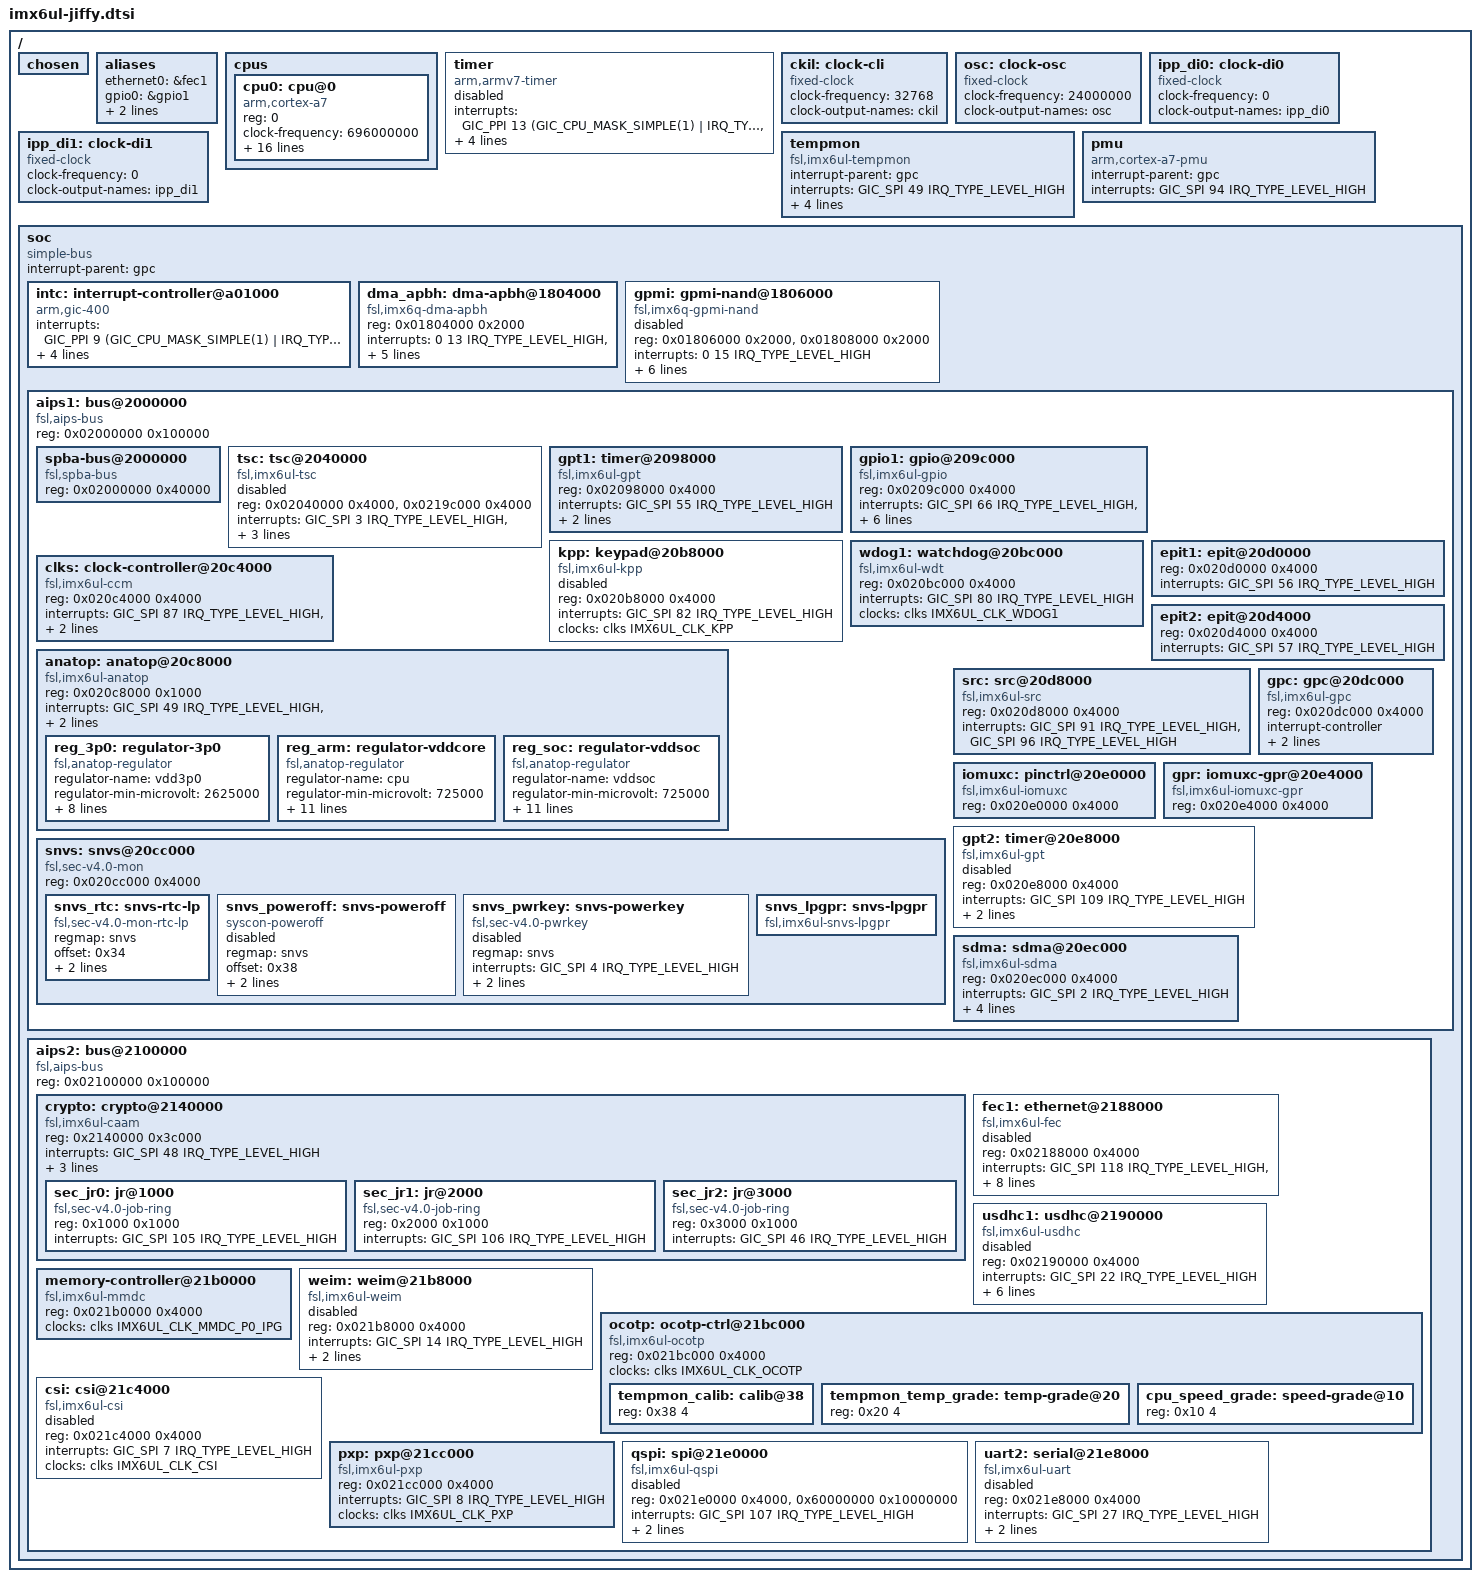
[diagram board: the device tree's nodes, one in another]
// SPDX-License-Identifier: GPL-2.0
//
// Copyright 2015 Freescale Semiconductor, Inc.

#include <dt-bindings/clock/imx6ul-clock.h>
#include <dt-bindings/gpio/gpio.h>
#include <dt-bindings/input/input.h>
#include <dt-bindings/interrupt-controller/arm-gic.h>
#include "imx6ul-pinfunc.h"

/ {
	#address-cells = <1>;
	#size-cells = <1>;
	/*
	 * The decompressor and also some bootloaders rely on a
	 * pre-existing /chosen node to be available to insert the
	 * command line and merge other ATAGS info.
	 */
	chosen {};

	aliases {
		ethernet0 = &fec1;
		gpio0 = &gpio1;
		mmc0 = &usdhc1;
		serial1 = &uart2;
	};

	cpus {
		#address-cells = <1>;
		#size-cells = <0>;

		cpu0: cpu@0 {
			compatible = "arm,cortex-a7";
			device_type = "cpu";
			reg = <0>;
			clock-frequency = <696000000>;
			clock-latency = <61036>; /* two CLK32 periods */
			#cooling-cells = <2>;
			operating-points = <
				/* kHz	uV */
				696000	1275000
				528000	1175000
				396000	1025000
				198000	950000
			>;
			fsl,soc-operating-points = <
				/* KHz	uV */
				696000	1275000
				528000	1175000
				396000	1175000
				198000	1175000
			>;
			clocks = <&clks IMX6UL_CLK_ARM>,
				 <&clks IMX6UL_CLK_PLL2_BUS>,
				 <&clks IMX6UL_CLK_PLL2_PFD2>,
				 <&clks IMX6UL_CA7_SECONDARY_SEL>,
				 <&clks IMX6UL_CLK_STEP>,
				 <&clks IMX6UL_CLK_PLL1_SW>,
				 <&clks IMX6UL_CLK_PLL1_SYS>;
			clock-names = "arm", "pll2_bus",  "pll2_pfd2_396m",
				      "secondary_sel", "step", "pll1_sw",
				      "pll1_sys";
			arm-supply = <&reg_arm>;
			soc-supply = <&reg_soc>;
			nvmem-cells = <&cpu_speed_grade>;
			nvmem-cell-names = "speed_grade";
		};
	};

	timer {
		compatible = "arm,armv7-timer";
		interrupts = <GIC_PPI 13 (GIC_CPU_MASK_SIMPLE(1) | IRQ_TYPE_LEVEL_LOW)>,
			     <GIC_PPI 14 (GIC_CPU_MASK_SIMPLE(1) | IRQ_TYPE_LEVEL_LOW)>,
			     <GIC_PPI 11 (GIC_CPU_MASK_SIMPLE(1) | IRQ_TYPE_LEVEL_LOW)>,
			     <GIC_PPI 10 (GIC_CPU_MASK_SIMPLE(1) | IRQ_TYPE_LEVEL_LOW)>;
		interrupt-parent = <&intc>;
		status = "disabled";
	};

	ckil: clock-cli {
		compatible = "fixed-clock";
		#clock-cells = <0>;
		clock-frequency = <32768>;
		clock-output-names = "ckil";
	};

	osc: clock-osc {
		compatible = "fixed-clock";
		#clock-cells = <0>;
		clock-frequency = <24000000>;
		clock-output-names = "osc";
	};

	ipp_di0: clock-di0 {
		compatible = "fixed-clock";
		#clock-cells = <0>;
		clock-frequency = <0>;
		clock-output-names = "ipp_di0";
	};

	ipp_di1: clock-di1 {
		compatible = "fixed-clock";
		#clock-cells = <0>;
		clock-frequency = <0>;
		clock-output-names = "ipp_di1";
	};

	tempmon: tempmon {
		compatible = "fsl,imx6ul-tempmon", "fsl,imx6sx-tempmon";
		interrupt-parent = <&gpc>;
		interrupts = <GIC_SPI 49 IRQ_TYPE_LEVEL_HIGH>;
		fsl,tempmon = <&anatop>;
		nvmem-cells = <&tempmon_calib>, <&tempmon_temp_grade>;
		nvmem-cell-names = "calib", "temp_grade";
		clocks = <&clks IMX6UL_CLK_PLL3_USB_OTG>;
	};

	pmu {
		compatible = "arm,cortex-a7-pmu";
		interrupt-parent = <&gpc>;
		interrupts = <GIC_SPI 94 IRQ_TYPE_LEVEL_HIGH>;
	};

	soc {
		#address-cells = <1>;
		#size-cells = <1>;
		compatible = "simple-bus";
		interrupt-parent = <&gpc>;
		ranges;

		intc: interrupt-controller@a01000 {
			compatible = "arm,gic-400", "arm,cortex-a7-gic";
			interrupts = <GIC_PPI 9 (GIC_CPU_MASK_SIMPLE(1) | IRQ_TYPE_LEVEL_HIGH)>;
			#interrupt-cells = <3>;
			interrupt-controller;
			interrupt-parent = <&intc>;
			reg = <0x00a01000 0x1000>,
			      <0x00a02000 0x2000>,
			      <0x00a04000 0x2000>,
			      <0x00a06000 0x2000>;
		};

		dma_apbh: dma-apbh@1804000 {
			compatible = "fsl,imx6q-dma-apbh", "fsl,imx28-dma-apbh";
			reg = <0x01804000 0x2000>;
			interrupts = <0 13 IRQ_TYPE_LEVEL_HIGH>,
				     <0 13 IRQ_TYPE_LEVEL_HIGH>,
				     <0 13 IRQ_TYPE_LEVEL_HIGH>,
				     <0 13 IRQ_TYPE_LEVEL_HIGH>;
			interrupt-names = "gpmi0", "gpmi1", "gpmi2", "gpmi3";
			#dma-cells = <1>;
			dma-channels = <4>;
			clocks = <&clks IMX6UL_CLK_APBHDMA>;
		};

		gpmi: gpmi-nand@1806000 {
			compatible = "fsl,imx6q-gpmi-nand";
			#address-cells = <1>;
			#size-cells = <1>;
			reg = <0x01806000 0x2000>, <0x01808000 0x2000>;
			reg-names = "gpmi-nand", "bch";
			interrupts = <0 15 IRQ_TYPE_LEVEL_HIGH>;
			interrupt-names = "bch";
			clocks = <&clks IMX6UL_CLK_GPMI_IO>,
				 <&clks IMX6UL_CLK_GPMI_APB>,
				 <&clks IMX6UL_CLK_GPMI_BCH>,
				 <&clks IMX6UL_CLK_GPMI_BCH_APB>,
				 <&clks IMX6UL_CLK_PER_BCH>;
			clock-names = "gpmi_io", "gpmi_apb", "gpmi_bch",
				      "gpmi_bch_apb", "per1_bch";
			dmas = <&dma_apbh 0>;
			dma-names = "rx-tx";
			status = "disabled";
		};

		aips1: bus@2000000 {
			compatible = "fsl,aips-bus", "simple-bus";
			#address-cells = <1>;
			#size-cells = <1>;
			reg = <0x02000000 0x100000>;
			ranges;

			spba-bus@2000000 {
				compatible = "fsl,spba-bus", "simple-bus";
				#address-cells = <1>;
				#size-cells = <1>;
				reg = <0x02000000 0x40000>;
				ranges;
			};

			tsc: tsc@2040000 {
				compatible = "fsl,imx6ul-tsc";
				reg = <0x02040000 0x4000>, <0x0219c000 0x4000>;
				interrupts = <GIC_SPI 3 IRQ_TYPE_LEVEL_HIGH>,
					     <GIC_SPI 101 IRQ_TYPE_LEVEL_HIGH>;
				clocks = <&clks IMX6UL_CLK_IPG>,
					 <&clks IMX6UL_CLK_ADC2>;
				clock-names = "tsc", "adc";
				status = "disabled";
			};

			gpt1: timer@2098000 {
				compatible = "fsl,imx6ul-gpt", "fsl,imx6sx-gpt";
				reg = <0x02098000 0x4000>;
				interrupts = <GIC_SPI 55 IRQ_TYPE_LEVEL_HIGH>;
				clocks = <&clks IMX6UL_CLK_GPT1_BUS>,
					 <&clks IMX6UL_CLK_GPT1_SERIAL>;
				clock-names = "ipg", "per";
			};

			gpio1: gpio@209c000 {
				compatible = "fsl,imx6ul-gpio", "fsl,imx35-gpio";
				reg = <0x0209c000 0x4000>;
				interrupts = <GIC_SPI 66 IRQ_TYPE_LEVEL_HIGH>,
					     <GIC_SPI 67 IRQ_TYPE_LEVEL_HIGH>;
				clocks = <&clks IMX6UL_CLK_GPIO1>;
				gpio-controller;
				#gpio-cells = <2>;
				interrupt-controller;
				#interrupt-cells = <2>;
				gpio-ranges = <&iomuxc  0 23 10>, <&iomuxc 10 17 6>,
					      <&iomuxc 16 33 16>;
			};

			kpp: keypad@20b8000 {
				compatible = "fsl,imx6ul-kpp", "fsl,imx6q-kpp", "fsl,imx21-kpp";
				reg = <0x020b8000 0x4000>;
				interrupts = <GIC_SPI 82 IRQ_TYPE_LEVEL_HIGH>;
				clocks = <&clks IMX6UL_CLK_KPP>;
				status = "disabled";
			};

			wdog1: watchdog@20bc000 {
				compatible = "fsl,imx6ul-wdt", "fsl,imx21-wdt";
				reg = <0x020bc000 0x4000>;
				interrupts = <GIC_SPI 80 IRQ_TYPE_LEVEL_HIGH>;
				clocks = <&clks IMX6UL_CLK_WDOG1>;
			};

			clks: clock-controller@20c4000 {
				compatible = "fsl,imx6ul-ccm";
				reg = <0x020c4000 0x4000>;
				interrupts = <GIC_SPI 87 IRQ_TYPE_LEVEL_HIGH>,
					     <GIC_SPI 88 IRQ_TYPE_LEVEL_HIGH>;
				#clock-cells = <1>;
				clocks = <&ckil>, <&osc>, <&ipp_di0>, <&ipp_di1>;
				clock-names = "ckil", "osc", "ipp_di0", "ipp_di1";
			};

			anatop: anatop@20c8000 {
				compatible = "fsl,imx6ul-anatop", "fsl,imx6q-anatop",
					     "syscon", "simple-mfd";
				reg = <0x020c8000 0x1000>;
				interrupts = <GIC_SPI 49 IRQ_TYPE_LEVEL_HIGH>,
					     <GIC_SPI 54 IRQ_TYPE_LEVEL_HIGH>,
					     <GIC_SPI 127 IRQ_TYPE_LEVEL_HIGH>;

				reg_3p0: regulator-3p0 {
					compatible = "fsl,anatop-regulator";
					regulator-name = "vdd3p0";
					regulator-min-microvolt = <2625000>;
					regulator-max-microvolt = <3400000>;
					anatop-reg-offset = <0x120>;
					anatop-vol-bit-shift = <8>;
					anatop-vol-bit-width = <5>;
					anatop-min-bit-val = <0>;
					anatop-min-voltage = <2625000>;
					anatop-max-voltage = <3400000>;
					anatop-enable-bit = <0>;
				};

				reg_arm: regulator-vddcore {
					compatible = "fsl,anatop-regulator";
					regulator-name = "cpu";
					regulator-min-microvolt = <725000>;
					regulator-max-microvolt = <1450000>;
					regulator-always-on;
					anatop-reg-offset = <0x140>;
					anatop-vol-bit-shift = <0>;
					anatop-vol-bit-width = <5>;
					anatop-delay-reg-offset = <0x170>;
					anatop-delay-bit-shift = <24>;
					anatop-delay-bit-width = <2>;
					anatop-min-bit-val = <1>;
					anatop-min-voltage = <725000>;
					anatop-max-voltage = <1450000>;
				};

				reg_soc: regulator-vddsoc {
					compatible = "fsl,anatop-regulator";
					regulator-name = "vddsoc";
					regulator-min-microvolt = <725000>;
					regulator-max-microvolt = <1450000>;
					regulator-always-on;
					anatop-reg-offset = <0x140>;
					anatop-vol-bit-shift = <18>;
					anatop-vol-bit-width = <5>;
					anatop-delay-reg-offset = <0x170>;
					anatop-delay-bit-shift = <28>;
					anatop-delay-bit-width = <2>;
					anatop-min-bit-val = <1>;
					anatop-min-voltage = <725000>;
					anatop-max-voltage = <1450000>;
				};
			};

			snvs: snvs@20cc000 {
				compatible = "fsl,sec-v4.0-mon", "syscon", "simple-mfd";
				reg = <0x020cc000 0x4000>;

				snvs_rtc: snvs-rtc-lp {
					compatible = "fsl,sec-v4.0-mon-rtc-lp";
					regmap = <&snvs>;
					offset = <0x34>;
					interrupts = <GIC_SPI 19 IRQ_TYPE_LEVEL_HIGH>,
						     <GIC_SPI 20 IRQ_TYPE_LEVEL_HIGH>;
				};

				snvs_poweroff: snvs-poweroff {
					compatible = "syscon-poweroff";
					regmap = <&snvs>;
					offset = <0x38>;
					value = <0x60>;
					mask = <0x60>;
					status = "disabled";
				};

				snvs_pwrkey: snvs-powerkey {
					compatible = "fsl,sec-v4.0-pwrkey";
					regmap = <&snvs>;
					interrupts = <GIC_SPI 4 IRQ_TYPE_LEVEL_HIGH>;
					linux,keycode = <KEY_POWER>;
					wakeup-source;
					status = "disabled";
				};

				snvs_lpgpr: snvs-lpgpr {
					compatible = "fsl,imx6ul-snvs-lpgpr";
				};
			};

			epit1: epit@20d0000 {
				reg = <0x020d0000 0x4000>;
				interrupts = <GIC_SPI 56 IRQ_TYPE_LEVEL_HIGH>;
			};

			epit2: epit@20d4000 {
				reg = <0x020d4000 0x4000>;
				interrupts = <GIC_SPI 57 IRQ_TYPE_LEVEL_HIGH>;
			};

			src: src@20d8000 {
				compatible = "fsl,imx6ul-src", "fsl,imx51-src";
				reg = <0x020d8000 0x4000>;
				interrupts = <GIC_SPI 91 IRQ_TYPE_LEVEL_HIGH>,
					     <GIC_SPI 96 IRQ_TYPE_LEVEL_HIGH>;
				#reset-cells = <1>;
			};

			gpc: gpc@20dc000 {
				compatible = "fsl,imx6ul-gpc", "fsl,imx6q-gpc";
				reg = <0x020dc000 0x4000>;
				interrupt-controller;
				#interrupt-cells = <3>;
				interrupts = <GIC_SPI 89 IRQ_TYPE_LEVEL_HIGH>;
				interrupt-parent = <&intc>;
			};

			iomuxc: pinctrl@20e0000 {
				compatible = "fsl,imx6ul-iomuxc";
				reg = <0x020e0000 0x4000>;
			};

			gpr: iomuxc-gpr@20e4000 {
				compatible = "fsl,imx6ul-iomuxc-gpr",
					     "fsl,imx6q-iomuxc-gpr", "syscon";
				reg = <0x020e4000 0x4000>;
			};

			gpt2: timer@20e8000 {
				compatible = "fsl,imx6ul-gpt", "fsl,imx6sx-gpt";
				reg = <0x020e8000 0x4000>;
				interrupts = <GIC_SPI 109 IRQ_TYPE_LEVEL_HIGH>;
				clocks = <&clks IMX6UL_CLK_GPT2_BUS>,
					 <&clks IMX6UL_CLK_GPT2_SERIAL>;
				clock-names = "ipg", "per";
				status = "disabled";
			};

			sdma: sdma@20ec000 {
				compatible = "fsl,imx6ul-sdma", "fsl,imx6q-sdma",
					     "fsl,imx35-sdma";
				reg = <0x020ec000 0x4000>;
				interrupts = <GIC_SPI 2 IRQ_TYPE_LEVEL_HIGH>;
				clocks = <&clks IMX6UL_CLK_IPG>,
					 <&clks IMX6UL_CLK_SDMA>;
				clock-names = "ipg", "ahb";
				#dma-cells = <3>;
				fsl,sdma-ram-script-name = "imx/sdma/sdma-imx6q.bin";
			};
		};

		aips2: bus@2100000 {
			compatible = "fsl,aips-bus", "simple-bus";
			#address-cells = <1>;
			#size-cells = <1>;
			reg = <0x02100000 0x100000>;
			ranges;

			crypto: crypto@2140000 {
				compatible = "fsl,imx6ul-caam", "fsl,sec-v4.0";
				#address-cells = <1>;
				#size-cells = <1>;
				reg = <0x2140000 0x3c000>;
				ranges = <0 0x2140000 0x3c000>;
				interrupts = <GIC_SPI 48 IRQ_TYPE_LEVEL_HIGH>;
				clocks = <&clks IMX6UL_CLK_CAAM_IPG>, <&clks IMX6UL_CLK_CAAM_ACLK>,
					 <&clks IMX6UL_CLK_CAAM_MEM>;
				clock-names = "ipg", "aclk", "mem";

				sec_jr0: jr@1000 {
					compatible = "fsl,sec-v4.0-job-ring";
					reg = <0x1000 0x1000>;
					interrupts = <GIC_SPI 105 IRQ_TYPE_LEVEL_HIGH>;
				};

				sec_jr1: jr@2000 {
					compatible = "fsl,sec-v4.0-job-ring";
					reg = <0x2000 0x1000>;
					interrupts = <GIC_SPI 106 IRQ_TYPE_LEVEL_HIGH>;
				};

				sec_jr2: jr@3000 {
					compatible = "fsl,sec-v4.0-job-ring";
					reg = <0x3000 0x1000>;
					interrupts = <GIC_SPI 46 IRQ_TYPE_LEVEL_HIGH>;
				};
			};

			fec1: ethernet@2188000 {
				compatible = "fsl,imx6ul-fec", "fsl,imx6q-fec";
				reg = <0x02188000 0x4000>;
				interrupt-names = "int0", "pps";
				interrupts = <GIC_SPI 118 IRQ_TYPE_LEVEL_HIGH>,
					     <GIC_SPI 119 IRQ_TYPE_LEVEL_HIGH>;
				clocks = <&clks IMX6UL_CLK_ENET>,
					 <&clks IMX6UL_CLK_ENET_AHB>,
					 <&clks IMX6UL_CLK_ENET_PTP>,
					 <&clks IMX6UL_CLK_ENET_REF>,
					 <&clks IMX6UL_CLK_ENET_REF>;
				clock-names = "ipg", "ahb", "ptp",
					      "enet_clk_ref", "enet_out";
				fsl,num-tx-queues = <1>;
				fsl,num-rx-queues = <1>;
				status = "disabled";
			};

			usdhc1: usdhc@2190000 {
				compatible = "fsl,imx6ul-usdhc", "fsl,imx6sx-usdhc";
				reg = <0x02190000 0x4000>;
				interrupts = <GIC_SPI 22 IRQ_TYPE_LEVEL_HIGH>;
				clocks = <&clks IMX6UL_CLK_USDHC1>,
					 <&clks IMX6UL_CLK_USDHC1>,
					 <&clks IMX6UL_CLK_USDHC1>;
				clock-names = "ipg", "ahb", "per";
				fsl,tuning-step = <2>;
				fsl,tuning-start-tap = <20>;
				bus-width = <4>;
				status = "disabled";
			};

			memory-controller@21b0000 {
				compatible = "fsl,imx6ul-mmdc", "fsl,imx6q-mmdc";
				reg = <0x021b0000 0x4000>;
				clocks = <&clks IMX6UL_CLK_MMDC_P0_IPG>;
			};

			weim: weim@21b8000 {
				#address-cells = <2>;
				#size-cells = <1>;
				compatible = "fsl,imx6ul-weim", "fsl,imx6q-weim";
				reg = <0x021b8000 0x4000>;
				interrupts = <GIC_SPI 14 IRQ_TYPE_LEVEL_HIGH>;
				clocks = <&clks IMX6UL_CLK_EIM>;
				fsl,weim-cs-gpr = <&gpr>;
				status = "disabled";
			};

			ocotp: ocotp-ctrl@21bc000 {
				#address-cells = <1>;
				#size-cells = <1>;
				compatible = "fsl,imx6ul-ocotp", "syscon";
				reg = <0x021bc000 0x4000>;
				clocks = <&clks IMX6UL_CLK_OCOTP>;

				tempmon_calib: calib@38 {
					reg = <0x38 4>;
				};

				tempmon_temp_grade: temp-grade@20 {
					reg = <0x20 4>;
				};

				cpu_speed_grade: speed-grade@10 {
					reg = <0x10 4>;
				};
			};

			csi: csi@21c4000 {
				compatible = "fsl,imx6ul-csi", "fsl,imx7-csi";
				reg = <0x021c4000 0x4000>;
				interrupts = <GIC_SPI 7 IRQ_TYPE_LEVEL_HIGH>;
				clocks = <&clks IMX6UL_CLK_CSI>;
				clock-names = "mclk";
				status = "disabled";
			};

			pxp: pxp@21cc000 {
				compatible = "fsl,imx6ul-pxp";
				reg = <0x021cc000 0x4000>;
				interrupts = <GIC_SPI 8 IRQ_TYPE_LEVEL_HIGH>;
				clocks = <&clks IMX6UL_CLK_PXP>;
				clock-names = "axi";
			};

			qspi: spi@21e0000 {
				#address-cells = <1>;
				#size-cells = <0>;
				compatible = "fsl,imx6ul-qspi", "fsl,imx6sx-qspi";
				reg = <0x021e0000 0x4000>, <0x60000000 0x10000000>;
				reg-names = "QuadSPI", "QuadSPI-memory";
				interrupts = <GIC_SPI 107 IRQ_TYPE_LEVEL_HIGH>;
				clocks = <&clks IMX6UL_CLK_QSPI>,
					 <&clks IMX6UL_CLK_QSPI>;
				clock-names = "qspi_en", "qspi";
				status = "disabled";
			};

			uart2: serial@21e8000 {
				compatible = "fsl,imx6ul-uart",
					     "fsl,imx6q-uart";
				reg = <0x021e8000 0x4000>;
				interrupts = <GIC_SPI 27 IRQ_TYPE_LEVEL_HIGH>;
				clocks = <&clks IMX6UL_CLK_UART2_IPG>,
					 <&clks IMX6UL_CLK_UART2_SERIAL>;
				clock-names = "ipg", "per";
				status = "disabled";
			};
		};
	};
};
